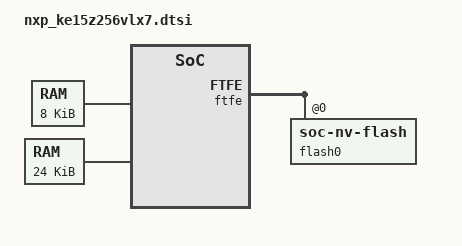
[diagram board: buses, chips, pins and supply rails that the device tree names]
/*
 *
 * SPDX-License-Identifier: Apache-2.0
 */

#include <mem.h>
#include <nxp/nxp_ke1xz.dtsi>

/ {
	sram_l: memory@1fffe000 {
		compatible = "zephyr,memory-region", "mmio-sram";
		reg = <0x1FFFE000 DT_SIZE_K(8)>;
		zephyr,memory-region = "SRAML";
	};

	sram0: memory@20000000 {
		compatible = "mmio-sram";
		reg = <0x20000000 DT_SIZE_K(24)>;
	};
};

&ftfe {
	flash0: flash@0 {
		compatible = "soc-nv-flash";
		reg = <0 DT_SIZE_K(256)>;
		erase-block-size = <DT_SIZE_K(2)>;
		write-block-size = <8>;
	};
};
